# PY32T020xx register map
Vendor: Puya; Series: PY32L0; File version: 1.0.0
CPU: CM0+ r0p1, little endian, no MPU, no FPU, 4 interrupt priority bits
Registers are 32-bit, read-write, reset 0x0 unless marked. A register's access mark holds for its fields unless they carry their own. Offsets are from the block's base; [hi:lo] are bit positions; {n}, {i} and the like mark numbered series.

## GPIOF
Base 0x50001400
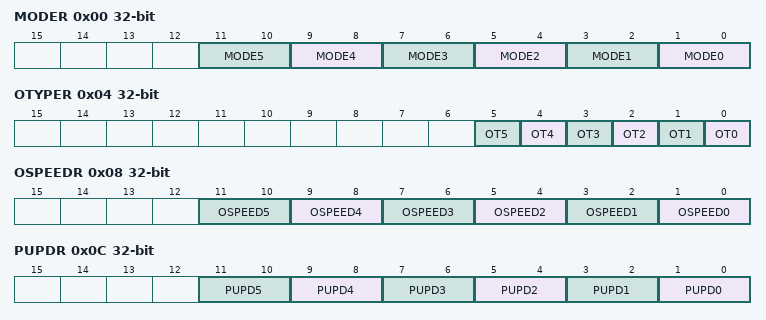
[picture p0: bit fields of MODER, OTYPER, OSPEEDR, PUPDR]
0x00 MODER
  [2n+1:2n] MODE{n} (n=0..5) — Port x configuration bits (y = 0..15)
0x04 OTYPER — GPIO port output type register
  [n] OT{n} (n=0..5) — Port x configuration bits (y = 0..15)
0x08 OSPEEDR — GPIO port output speed register
  [2n+1:2n] OSPEED{n} (n=0..5) — Port x configuration bits (y = 0..15)
0x0C PUPDR — GPIO port pull-up/pull-down register
  [2n+1:2n] PUPD{n} (n=0..5) — Port x configuration bits (y = 0..15)
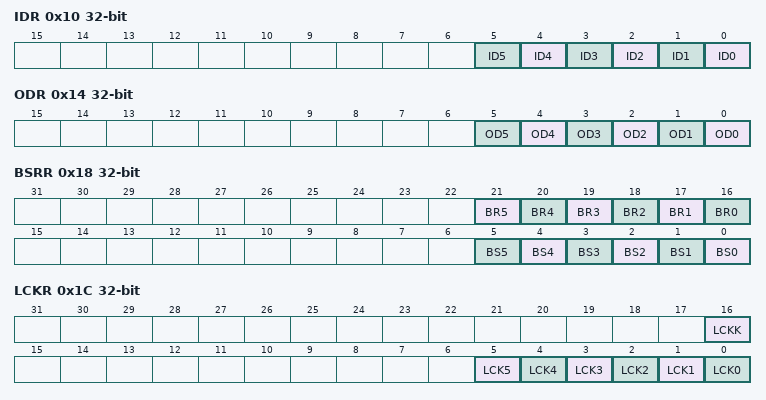
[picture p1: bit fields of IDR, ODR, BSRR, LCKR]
0x10 IDR — GPIO port input data register
  [n] ID{n} ro (n=0..5) — Port input data (y = 0..15)
0x14 ODR — GPIO port output data register
  [n] OD{n} (n=0..5) — Port output data (y = 0..15)
0x18 BSRR — GPIO port bit set/reset register
  [n+16] BR{n} (n=1..5) — Port x reset bit y (y = 0..15)
  [16] BR0 — Port x set bit y (y= 0..15)
  [n] BS{n} (n=0..5) — Port x set bit y (y= 0..15)
0x1C LCKR — GPIO port configuration lock register
  [16] LCKK — Port x lock bit y (y= 0..15)
  [n] LCK{n} (n=0..5) — Port x lock bit y (y= 0..15)
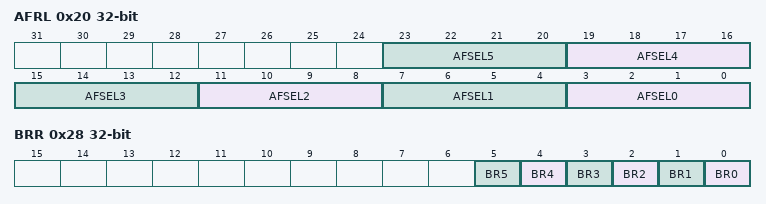
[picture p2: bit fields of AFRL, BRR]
0x20 AFRL — GPIO alternate function low register
  [4n+3:4n] AFSEL{n} (n=0..5) — Alternate function selection for port x bit y (y = 0..7)
0x28 BRR — port bit reset register
  [n] BR{n} (n=0..5) — Port Reset bit

## I2C — Inter integrated circuit
Base 0x40005400
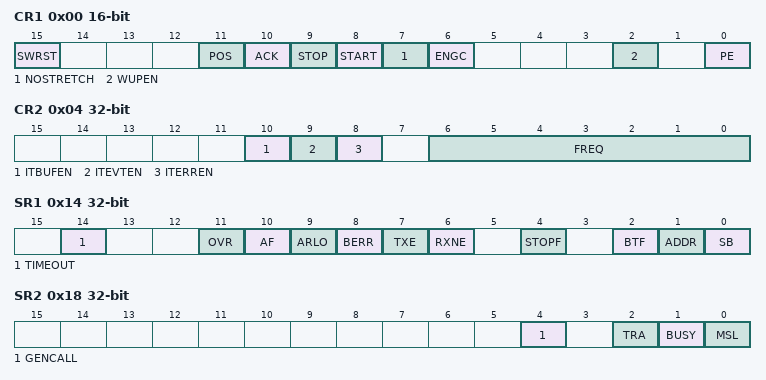
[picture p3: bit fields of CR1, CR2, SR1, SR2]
0x00 CR1 16-bit — Control register 1
  [15] SWRST — Software reset
  [11] POS — Acknowledge(for data reception)
  [10] ACK — Acknowledge enable
  [9] STOP — Stop generation
  [8] START — Start generation
  [7] NOSTRETCH — Clock stretching disable (Slave mode)
  [6] ENGC — General call enable
  [2] WUPEN — Wakeup from Stop mode enable
  [0] PE — Peripheral enable
0x04 CR2 — Control register 2
  [10] ITBUFEN — Buffer interrupt enable
  [9] ITEVTEN — Event interrupt enable
  [8] ITERREN — Error interrupt enable
  [6:0] FREQ — Peripheral clock frequency
0x08 OAR1 — Own address register 1
  [7:1] ADD — Interface address
0x10 DR — Data register
  [7:0] DR — 8-bit data register
0x14 SR1 — Status register 1
  [14] TIMEOUT — Timeout or Tlow error
  [11] OVR — Overrun/Underrun
  [10] AF — Acknowledge failure
  [9] ARLO — Arbitration lost (master mode)
  [8] BERR — Bus error
  [7] TXE ro — Data register empty (transmitters)
  [6] RXNE ro — Data register not empty (receivers)
  [4] STOPF ro — Stop detection (slave mode)
  [2] BTF ro — Byte transfer finished
  [1] ADDR ro — Address sent (master mode)/matched (slave mode)
  [0] SB ro — Start bit (Master mode)
0x18 SR2 — Status register 2
  [4] GENCALL ro — General call address (Slave mode)
  [2] TRA ro — Transmitter/receiver
  [1] BUSY ro — Bus busy
  [0] MSL ro — Master/slave
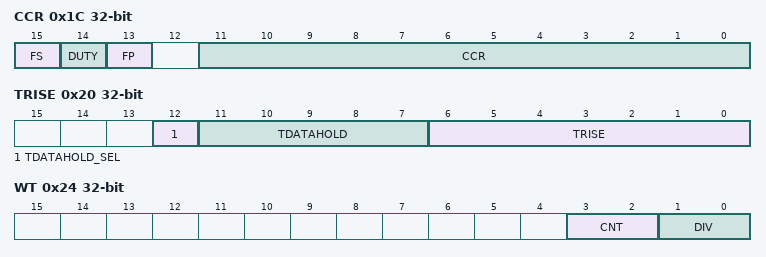
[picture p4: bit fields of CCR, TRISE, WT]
0x1C CCR — Clock control register
  [15] FS — I2C master mode selection
  [14] DUTY — Fm mode duty cycle
  [13] FP — I2C master mode selection
  [11:0] CCR — Clock control register in Fm/Sm mode (Master mode)
0x20 TRISE
  [12] TDATAHOLD_SEL — Data hold time select
  [11:7] TDATAHOLD — Data hold time
  [6:0] TRISE — Maximum rise time in Fm+/Fm/Sm mode (Master mode)
0x24 WT — Wakeup Time register
  [3:2] CNT — Timeout count number
  [1:0] DIV — PCLK division

## IWDG — Independent watchdog
Base 0x40003000
0x00 KR — Key register (IWDG_KR)
  [15:0] KEY wo — Key value
0x04 PR — Prescaler register (IWDG_PR)
  [2:0] PR — Prescaler divider
0x08 RLR — Reload register (IWDG_RLR)
  [11:0] RL — Watchdog counter reload value
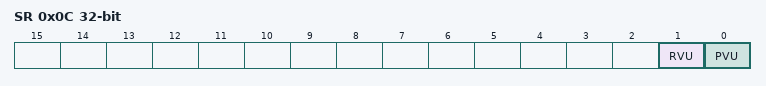
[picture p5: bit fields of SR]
0x0C SR — Status register (IWDG_SR)
  [1] RVU ro — Watchdog counter reload value update
  [0] PVU ro — Watchdog prescaler value update

## LPTIM1 — Low power timer
Base 0x40007C00
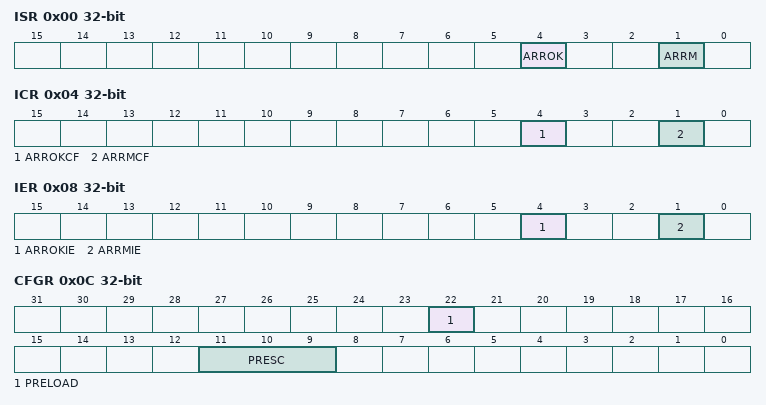
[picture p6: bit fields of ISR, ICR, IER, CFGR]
0x00 ISR ro — Interrupt and Status Register
  [4] ARROK — Autoreload match update OK
  [1] ARRM — Autoreload match
0x04 ICR wo — Interrupt Clear Register
  [4] ARROKCF — Autoreload match update OK Clear Flag
  [1] ARRMCF — Autoreload match Clear Flag
0x08 IER — Interrupt Enable Register
  [4] ARROKIE — Autoreload match update OK Interrupt Enable
  [1] ARRMIE — Autoreload matchInterrupt Enable
0x0C CFGR — Configuration Register
  [22] PRELOAD — Registers update mode
  [11:9] PRESC — Clock prescaler
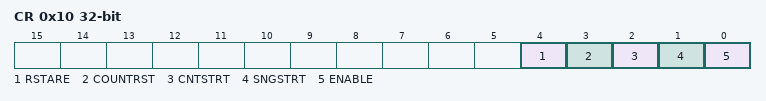
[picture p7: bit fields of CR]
0x10 CR — Control Register
  [4] RSTARE — Reset after read enable
  [3] COUNTRST — Reset counter
  [2] CNTSTRT
  [1] SNGSTRT — LPTIM start in single mode
  [0] ENABLE — LPTIM Enable
0x18 ARR reset 0x1 — Autoreload Register
  [15:0] ARR — Auto reload value
0x1C CNT ro — Counter Register
  [15:0] CNT — Counter value
